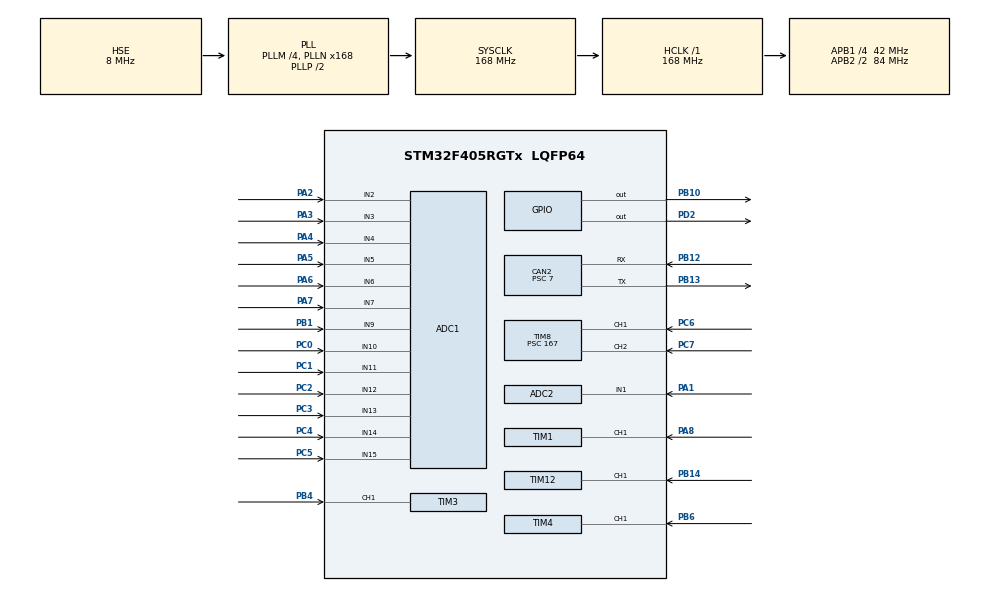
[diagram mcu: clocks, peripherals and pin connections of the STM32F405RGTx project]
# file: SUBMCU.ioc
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ADC1.Channel-0\#ChannelRegularConversion=ADC_CHANNEL_2
ADC1.ClockPrescaler=ADC_CLOCK_SYNC_PCLK_DIV4
ADC1.ContinuousConvMode=ENABLE
ADC1.DMAContinuousRequests=ENABLE
ADC1.NbrOfConversion=1
ADC1.NbrOfConversionFlag=1
ADC1.Rank-0\#ChannelRegularConversion=1
ADC1.SamplingTime-0\#ChannelRegularConversion=ADC_SAMPLETIME_3CYCLES
ADC1.master=1
ADC2.Channel-0\#ChannelRegularConversion=ADC_CHANNEL_5
ADC2.ClockPrescaler=ADC_CLOCK_SYNC_PCLK_DIV4
ADC2.NbrOfConversionFlag=1
ADC2.Rank-0\#ChannelRegularConversion=1
ADC2.SamplingTime-0\#ChannelRegularConversion=ADC_SAMPLETIME_3CYCLES
ADC3.Channel-0\#ChannelRegularConversion=ADC_CHANNEL_3
ADC3.ClockPrescaler=ADC_CLOCK_SYNC_PCLK_DIV4
ADC3.NbrOfConversionFlag=1
ADC3.Rank-0\#ChannelRegularConversion=1
ADC3.SamplingTime-0\#ChannelRegularConversion=ADC_SAMPLETIME_3CYCLES
CAN2.BS1=CAN_BS1_3TQ
CAN2.BS2=CAN_BS2_2TQ
CAN2.CalculateBaudRate=1000000
CAN2.CalculateTimeBit=999.99
CAN2.CalculateTimeQuantum=166.66666666666669
CAN2.Prescaler=7
CAN2.SJW=CAN_SJW_1TQ
Dma.ADC1.0.Direction=DMA_PERIPH_TO_MEMORY
Dma.ADC1.0.FIFOMode=DMA_FIFOMODE_DISABLE
Dma.ADC1.0.Instance=DMA2_Stream0
Dma.ADC1.0.MemDataAlignment=DMA_MDATAALIGN_WORD
Dma.ADC1.0.MemInc=DMA_MINC_ENABLE
Dma.ADC1.0.Mode=DMA_CIRCULAR
Dma.ADC1.0.PeriphDataAlignment=DMA_PDATAALIGN_WORD
Dma.ADC1.0.PeriphInc=DMA_PINC_DISABLE
Dma.ADC1.0.Priority=DMA_PRIORITY_LOW
Dma.Request0=ADC1
Mcu.Family=STM32F4
Mcu.Name=STM32F405RGTx
Mcu.Package=LQFP64
NVIC.CAN2_RX0_IRQn=true\:0\:0\:false\:false\:true\:true\:true
NVIC.CAN2_RX1_IRQn=true\:0\:0\:false\:false\:true\:true\:true
NVIC.DMA2_Stream0_IRQn=true\:0\:0\:false\:false\:true\:false\:true
NVIC.PriorityGroup=NVIC_PRIORITYGROUP_4
NVIC.TIM1_CC_IRQn=true\:0\:0\:false\:false\:true\:true\:true
NVIC.TIM4_IRQn=true\:0\:0\:false\:false\:true\:true\:true
NVIC.TIM8_CC_IRQn=true\:0\:0\:false\:false\:true\:true\:true
PA1.Signal=ADCx_IN1
PA10.Signal=S_TIM1_CH3
PA11.Signal=S_TIM1_CH4
PA13.Mode=Trace_Asynchronous_SW
PA13.Signal=SYS_JTMS-SWDIO
PA14.Mode=Trace_Asynchronous_SW
PA14.Signal=SYS_JTCK-SWCLK
PA15.Signal=SPI3_NSS
PA2.Signal=ADCx_IN2
PA3.Signal=ADCx_IN3
PA4.Signal=SharedAnalog_PA4
PA5.Signal=ADCx_IN5
PA6.Signal=ADCx_IN6
PA7.Signal=ADCx_IN7
PA8.Signal=S_TIM1_CH1
PA9.Signal=S_TIM1_CH2
PB1.Signal=ADCx_IN9
PB10.Signal=GPIO_Output
PB11.Signal=S_TIM2_CH4
PB12.Mode=CAN_Activate
PB12.Signal=CAN2_RX
PB13.Mode=CAN_Activate
PB13.Signal=CAN2_TX
PB14.Signal=S_TIM12_CH1
PB3.Mode=Trace_Asynchronous_SW
PB3.Signal=SYS_JTDO-SWO
PB4.Signal=S_TIM3_CH1
PB6.Signal=S_TIM4_CH1
PB8.Signal=I2C1_SCL
PB9.Signal=I2C1_SDA
PC0.Signal=ADCx_IN10
PC1.Signal=ADCx_IN11
PC10.Signal=SPI3_SCK
PC11.Signal=SPI3_MISO
PC12.Signal=SPI3_MOSI
PC2.Signal=ADCx_IN12
PC3.Signal=ADCx_IN13
PC4.Signal=ADCx_IN14
PC5.Signal=ADCx_IN15
PC6.Signal=S_TIM8_CH1
PC7.Signal=S_TIM8_CH2
PC8.Signal=S_TIM8_CH3
PC9.Signal=S_TIM8_CH4
PD2.Signal=GPIO_Output
PH0-OSC_IN.Mode=HSE-External-Oscillator
PH0-OSC_IN.Signal=RCC_OSC_IN
PH1-OSC_OUT.Mode=HSE-External-Oscillator
PH1-OSC_OUT.Signal=RCC_OSC_OUT
ProjectManager.HeapSize=0x200
ProjectManager.StackSize=0x400
ProjectManager.TargetToolchain=STM32CubeIDE
RCC.48MHZClocksFreq_Value=48000000
RCC.AHBFreq_Value=168000000
RCC.APB1CLKDivider=RCC_HCLK_DIV4
RCC.APB1Freq_Value=42000000
RCC.APB1TimFreq_Value=84000000
RCC.APB2CLKDivider=RCC_HCLK_DIV2
RCC.APB2Freq_Value=84000000
RCC.APB2TimFreq_Value=168000000
RCC.CortexFreq_Value=168000000
RCC.EnbaleCSS=true
RCC.HCLKFreq_Value=168000000
RCC.HSE_VALUE=8000000
RCC.HSI_VALUE=16000000
RCC.LSE_VALUE=32768
RCC.PLLM=4
RCC.PLLN=168
RCC.PLLQ=7
RCC.PLLSourceVirtual=RCC_PLLSOURCE_HSE
RCC.SYSCLKFreq_VALUE=168000000
RCC.SYSCLKSource=RCC_SYSCLKSOURCE_PLLCLK
RCC.VCOOutputFreq_Value=336000000
SH.ADCx_IN1.0=ADC1_IN1
SH.ADCx_IN1.1=ADC2_IN1,IN1
SH.ADCx_IN1.2=ADC3_IN1,IN1
SH.ADCx_IN10.0=ADC1_IN10,IN10
SH.ADCx_IN10.1=ADC2_IN10,IN10
SH.ADCx_IN10.2=ADC3_IN10,IN10
SH.ADCx_IN11.0=ADC1_IN11,IN11
SH.ADCx_IN11.1=ADC2_IN11,IN11
SH.ADCx_IN11.2=ADC3_IN11,IN11
SH.ADCx_IN12.0=ADC1_IN12,IN12
SH.ADCx_IN12.1=ADC2_IN12,IN12
SH.ADCx_IN12.2=ADC3_IN12,IN12
SH.ADCx_IN13.0=ADC1_IN13,IN13
SH.ADCx_IN13.1=ADC2_IN13,IN13
SH.ADCx_IN13.2=ADC3_IN13,IN13
SH.ADCx_IN14.0=ADC1_IN14,IN14
SH.ADCx_IN15.0=ADC1_IN15,IN15
SH.ADCx_IN2.0=ADC1_IN2,IN2
SH.ADCx_IN2.1=ADC2_IN2,IN2
SH.ADCx_IN2.2=ADC3_IN2,IN2
SH.ADCx_IN3.0=ADC1_IN3,IN3
SH.ADCx_IN3.1=ADC2_IN3,IN3
SH.ADCx_IN3.2=ADC3_IN3,IN3
SH.ADCx_IN5.0=ADC1_IN5,IN5
SH.ADCx_IN5.1=ADC2_IN5,IN5
SH.ADCx_IN6.0=ADC1_IN6,IN6
SH.ADCx_IN7.0=ADC1_IN7,IN7
SH.ADCx_IN9.0=ADC1_IN9,IN9
SH.S_TIM12_CH1.0=TIM12_CH1,Input_Capture1_from_TI1
SH.S_TIM12_CH1.1=TIM12_CH1,Input_Capture2_from_TI1
SH.S_TIM12_CH1.2=TIM12_CH1,TriggerSource_TI1FP1
SH.S_TIM1_CH1.0=TIM1_CH1,Input_Capture1_from_TI1
SH.S_TIM1_CH1.1=TIM1_CH1,Input_Capture2_from_TI1
SH.S_TIM1_CH1.2=TIM1_CH1,TriggerSource_TI1FP1
SH.S_TIM1_CH2.0=TIM1_CH2
SH.S_TIM1_CH3.0=TIM1_CH3
SH.S_TIM1_CH4.0=TIM1_CH4
SH.S_TIM2_CH4.0=TIM2_CH4
SH.S_TIM3_CH1.0=TIM3_CH1,TriggerSource_TI1ED
SH.S_TIM4_CH1.0=TIM4_CH1,Input_Capture1_from_TI1
SH.S_TIM4_CH1.1=TIM4_CH1,Input_Capture2_from_TI1
SH.S_TIM4_CH1.2=TIM4_CH1,TriggerSource_TI1FP1
SH.S_TIM8_CH1.0=TIM8_CH1,Input_Capture1_from_TI1
SH.S_TIM8_CH1.1=TIM8_CH1,Input_Capture2_from_TI1
SH.S_TIM8_CH2.0=TIM8_CH2,TriggerSource_TI2FP2
SH.S_TIM8_CH3.0=TIM8_CH3
SH.S_TIM8_CH4.0=TIM8_CH4
SH.SharedAnalog_PA4.0=ADC1_IN4,IN4
SH.SharedAnalog_PA4.1=ADC2_IN4,IN4
SH.SharedAnalog_PA4.2=DAC_OUT1,DAC_OUT1
TIM1.AutoReloadPreload=TIM_AUTORELOAD_PRELOAD_ENABLE
TIM1.Channel-Input_Capture1_from_TI1=TIM_CHANNEL_1
TIM1.Channel-Input_Capture2_from_TI1=TIM_CHANNEL_2
TIM1.ICFilter_CH1=15
TIM1.ICPolarity_CH2=TIM_INPUTCHANNELPOLARITY_FALLING
TIM1.Period=65535
TIM1.Prescaler=167
TIM12.Channel-Input_Capture1_from_TI1=TIM_CHANNEL_1
TIM12.Channel-Input_Capture2_from_TI1=TIM_CHANNEL_2
TIM12.ICFilter_CH1=15
TIM12.ICPolarity_CH2=TIM_INPUTCHANNELPOLARITY_FALLING
TIM12.Prescaler=167
TIM3.Channel-Input_Capture1_from_TRC=TIM_CHANNEL_1
TIM4.Channel-Input_Capture1_from_TI1=TIM_CHANNEL_1
TIM4.Channel-Input_Capture2_from_TI1=TIM_CHANNEL_2
TIM4.ICFilter_CH1=15
TIM4.ICPolarity_CH2=TIM_INPUTCHANNELPOLARITY_FALLING
TIM4.Prescaler=167
TIM8.AutoReloadPreload=TIM_AUTORELOAD_PRELOAD_ENABLE
TIM8.Channel-Input_Capture1_from_TI1=TIM_CHANNEL_1
TIM8.Channel-Input_Capture2_from_TI1=TIM_CHANNEL_2
TIM8.ICFilter_CH1=15
TIM8.ICFilter_CH2=15
TIM8.ICPolarity_CH2=TIM_INPUTCHANNELPOLARITY_FALLING
TIM8.Prescaler=167
VP_CRC_VS_CRC.Mode=CRC_Activate
VP_TIM12_VS_ClockSourceINT.Mode=Internal
VP_TIM12_VS_ControllerModeReset.Mode=Reset Mode
VP_TIM1_VS_ControllerModeReset.Mode=Reset Mode
VP_TIM3_VS_CH1.Mode=Input_Capture1_from_TRC
VP_TIM3_VS_ClockSourceINT.Mode=Internal
VP_TIM4_VS_ClockSourceINT.Mode=Internal
VP_TIM4_VS_ControllerModeReset.Mode=Reset Mode
VP_TIM8_VS_ControllerModeReset.Mode=Reset Mode
board=custom

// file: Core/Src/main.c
/* USER CODE BEGIN Header */
/**
  ******************************************************************************
  * @file           : main.c
  * @brief          : Main program body
  ******************************************************************************
  * @attention
  *
  * <h2><center>&copy; Copyright (c) 2020 STMicroelectronics.
  * All rights reserved.</center></h2>
  *
  * This software component is licensed by ST under BSD 3-Clause license,
  * the "License"; You may not use this file except in compliance with the
  * License. You may obtain a copy of the License at:
  *                        opensource.org/licenses/BSD-3-Clause
  *
  ******************************************************************************
  */
/* USER CODE END Header */
#include "main.h"
#include "adc.h"
#include "can.h"
#include "crc.h"
#include "dac.h"
#include "dma.h"
#include "tim.h"
#include "gpio.h"

void SystemClock_Config(void);

int main(void)
{

  /* MCU Configuration--------------------------------------------------------*/

  /* Reset of all peripherals, Initializes the Flash interface and the Systick. */
  HAL_Init();

  /* Configure the system clock */
  SystemClock_Config();

  /* Initialize all configured peripherals */
  MX_GPIO_Init();
  MX_DMA_Init();
  MX_ADC1_Init();
  MX_ADC2_Init();
  MX_ADC3_Init();
  MX_CAN2_Init();
  MX_DAC_Init();
  MX_CRC_Init();
  MX_TIM1_Init();
  MX_TIM3_Init();
  MX_TIM8_Init();
  MX_TIM4_Init();
  MX_TIM12_Init();
  /* USER CODE BEGIN 2 */
  GAS_Scheduler_init();
  /* USER CODE END 2 */

  /* Infinite loop */
  while (1)
  {

    /* USER CODE BEGIN 3 */
		 GAS_Scheduler();
  }
  /* USER CODE END 3 */
}

void SystemClock_Config(void)
{
  RCC_OscInitTypeDef RCC_OscInitStruct = {0};
  RCC_ClkInitTypeDef RCC_ClkInitStruct = {0};

  /** Configure the main internal regulator output voltage
  */
  __HAL_RCC_PWR_CLK_ENABLE();
  __HAL_PWR_VOLTAGESCALING_CONFIG(PWR_REGULATOR_VOLTAGE_SCALE1);
  /** Initializes the RCC Oscillators according to the specified parameters
  * in the RCC_OscInitTypeDef structure.
  */
  RCC_OscInitStruct.OscillatorType = RCC_OSCILLATORTYPE_HSE;
  RCC_OscInitStruct.HSEState = RCC_HSE_ON;
  RCC_OscInitStruct.PLL.PLLState = RCC_PLL_ON;
  RCC_OscInitStruct.PLL.PLLSource = RCC_PLLSOURCE_HSE;
  RCC_OscInitStruct.PLL.PLLM = 4;
  RCC_OscInitStruct.PLL.PLLN = 168;
  RCC_OscInitStruct.PLL.PLLP = RCC_PLLP_DIV2;
  RCC_OscInitStruct.PLL.PLLQ = 7;
  if (HAL_RCC_OscConfig(&RCC_OscInitStruct) != HAL_OK)
  {
    Error_Handler();
  }
  /** Initializes the CPU, AHB and APB buses clocks
  */
  RCC_ClkInitStruct.ClockType = RCC_CLOCKTYPE_HCLK|RCC_CLOCKTYPE_SYSCLK
                              |RCC_CLOCKTYPE_PCLK1|RCC_CLOCKTYPE_PCLK2;
  RCC_ClkInitStruct.SYSCLKSource = RCC_SYSCLKSOURCE_PLLCLK;
  RCC_ClkInitStruct.AHBCLKDivider = RCC_SYSCLK_DIV1;
  RCC_ClkInitStruct.APB1CLKDivider = RCC_HCLK_DIV4;
  RCC_ClkInitStruct.APB2CLKDivider = RCC_HCLK_DIV2;

  if (HAL_RCC_ClockConfig(&RCC_ClkInitStruct, FLASH_LATENCY_5) != HAL_OK)
  {
    Error_Handler();
  }
  /** Enables the Clock Security System
  */
  HAL_RCC_EnableCSS();
}

void Error_Handler(void)
{
  __disable_irq();
  while (1)
  {
  }
}

/************************ (C) COPYRIGHT STMicroelectronics *****END OF FILE****/
